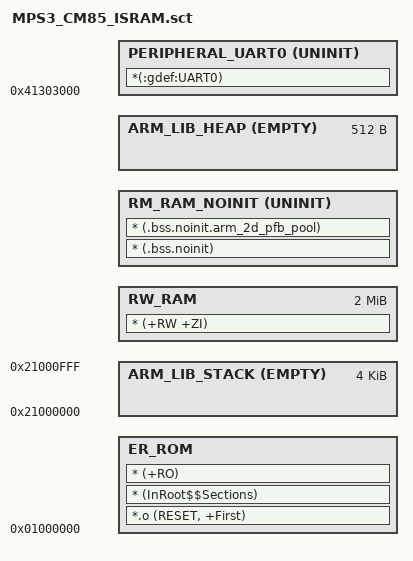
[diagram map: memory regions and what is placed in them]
#! armclang -E --target=arm-arm-none-eabi -mcpu=cortex-m85 -xc
; command above MUST be in first line (no comment above!)

/*
;-------- <<< Use Configuration Wizard in Context Menu >>> -------------------
*/

/*--------------------- Flash Configuration ----------------------------------
; <h> Flash Configuration
;   <o0> Flash Base Address <0x0-0xFFFFFFFF:8>
;   <o1> Flash Size (in Bytes) <0x0-0xFFFFFFFF:8>
; </h>
 *----------------------------------------------------------------------------*/
#define __ROM_BASE     0x01000000
#define __ROM_SIZE     0x00200000

/*--------------------- Embedded RAM Configuration ---------------------------
; <h> RAM Configuration
;   <o0> RAM Base Address    <0x0-0xFFFFFFFF:8>
;   <o1> RAM Size (in Bytes) <0x0-0xFFFFFFFF:8>
; </h>
 *----------------------------------------------------------------------------*/
#define __RAM_BASE     0x21000000
#define __RAM_SIZE     0x00200000

#define __HEAP_BASE     +0

/*--------------------- Stack / Heap Configuration ---------------------------
; <h> Stack / Heap Configuration
;   <o0> Stack Size (in Bytes) <0x0-0xFFFFFFFF:8>
;   <o1> Heap Size (in Bytes) <0x0-0xFFFFFFFF:8>
; </h>
 *----------------------------------------------------------------------------*/
#define __STACK_SIZE    0x00001000
#define __HEAP_SIZE     0x00000200

#define __RAM_RW_SIZE 	(__RAM_SIZE - __STACK_SIZE - __HEAP_SIZE)

LR_ROM __ROM_BASE __ROM_SIZE  {                                                 ; load region size_region
    ER_ROM +0 {                                                                 ; load address = execution address
        *.o (RESET, +First)
        * (InRoot$$Sections)
        ;   *(Veneer$$CMSE)                                                     ; uncomment for secure applications
        * (+RO)
        ;   * (+XO)
    }

    ARM_LIB_STACK __RAM_BASE ALIGN 8 EMPTY __STACK_SIZE {                      ; Reserve empty region for stack
    }

    RW_RAM +0 __RAM_RW_SIZE {
        * (+RW +ZI)
    }

    RM_RAM_NOINIT +0 UNINIT {
        * (.bss.noinit)
        * (.bss.noinit.arm_2d_pfb_pool)
    }

    ARM_LIB_HEAP  __HEAP_BASE ALIGN 8 EMPTY __HEAP_SIZE  {                      ; Reserve empty region for heap
    }

    PERIPHERAL_UART0 0x41303000 UNINIT {
        *(:gdef:UART0)
    }
}
